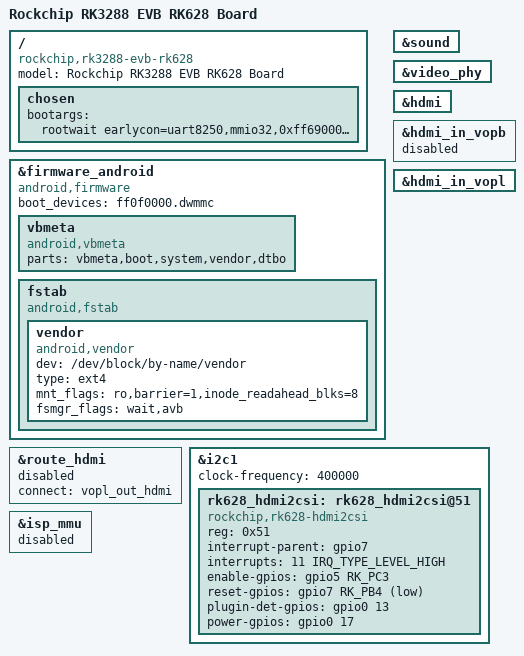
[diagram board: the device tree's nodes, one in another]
// SPDX-License-Identifier: (GPL-2.0+ OR MIT)
// Copyright (c) 2020 Fuzhou Rockchip Electronics Co., Ltd

/dts-v1/;
#include "rk3288-evb-rk628-csi.dtsi"

/ {
	model = "Rockchip RK3288 EVB RK628 Board";
	compatible = "rockchip,rk3288-evb-rk628", "rockchip,rk3288";

	chosen {
		bootargs = "rootwait earlycon=uart8250,mmio32,0xff690000 vmalloc=496M swiotlb=1 console=ttyFIQ0 androidboot.baseband=N/A androidboot.veritymode=enforcing androidboot.hardware=rk30board androidboot.console=ttyFIQ0 init=/init kpti=0 androidboot.selinux=permissive";
	};
};

&firmware_android {
	compatible = "android,firmware";
	boot_devices = "ff0f0000.dwmmc";

	vbmeta {
		compatible = "android,vbmeta";
		parts = "vbmeta,boot,system,vendor,dtbo";
	};

	fstab {
		compatible = "android,fstab";

		vendor {
			compatible = "android,vendor";
			dev = "/dev/block/by-name/vendor";
			type = "ext4";
			mnt_flags = "ro,barrier=1,inode_readahead_blks=8";
			fsmgr_flags = "wait,avb";
		};
	};
};

&sound {
	status = "okay";
};

&video_phy {
	status = "okay";
};

&hdmi {
	status = "okay";
};

&hdmi_in_vopb {
	status = "disabled";
};

&hdmi_in_vopl {
	status = "okay";
};

&route_hdmi {
	connect = <&vopl_out_hdmi>;
	status = "disabled";
};

&i2c1 {
	clock-frequency = <400000>;
	status = "okay";
	rk628_hdmi2csi: rk628_hdmi2csi@51 {
		reg = <0x51>;
		compatible = "rockchip,rk628-hdmi2csi";
		interrupt-parent = <&gpio7>;
		interrupts = <11 IRQ_TYPE_LEVEL_HIGH>;
		enable-gpios = <&gpio5 RK_PC3 GPIO_ACTIVE_HIGH>;
		reset-gpios = <&gpio7 RK_PB4 GPIO_ACTIVE_LOW>;
		plugin-det-gpios = <&gpio0 13 GPIO_ACTIVE_HIGH>;
		power-gpios = <&gpio0 17 GPIO_ACTIVE_HIGH>;
		status = "okay";
	};
};

&isp_mmu {
	status = "disabled";
};
